VERSION ""

NS_ :

BS_:
BU_:
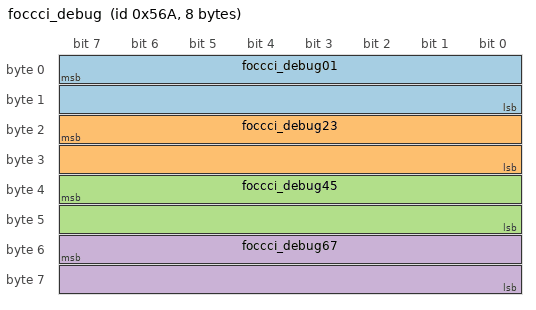
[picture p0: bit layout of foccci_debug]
BO_ 1386 foccci_debug: 8 Vector__XXX
   SG_ foccci_debug01 : 7|16@0- (1,0) [-32768|32767] "" Vector__XXX
   SG_ foccci_debug23 : 23|16@0- (1,0) [-32768|32767] "" Vector__XXX
   SG_ foccci_debug45 : 39|16@0- (1,0) [-32768|32767] "" Vector__XXX
   SG_ foccci_debug67 : 55|16@0- (1,0) [-32768|32767] "" Vector__XXX

BA_DEF_ BO_ "GenMsgBackgroundColor" STRING ;
BA_DEF_ BO_ "GenMsgForegroundColor" STRING ;
BA_DEF_ BO_ "filterlabeling" INT 0 0;
BA_ "GenMsgForegroundColor" BO_ 1386 "#0055ff";
BA_DEF_DEF_ "GenMsgBackgroundColor" "#ffffff";
BA_DEF_DEF_ "GenMsgForegroundColor" "#000000";
BA_DEF_DEF_ "filterlabeling" 1;
